# daric register map
Vendor: cramium
Registers are 32-bit, read-write, reset 0x0 unless marked. A register's access mark holds for its fields unless they carry their own. Offsets are from the block's base; [hi:lo] are bit positions; {n}, {i} and the like mark numbered series.

## UDMA_CAMERA
Base 0x5010F000
0x00 REG_RX_SADDR — See file:///F:/code/cram-nto/ips/udma/udma_camera/rtl/camera_reg_if.sv
  [11:0] r_rx_startaddr
0x04 REG_RX_SIZE — See file:///F:/code/cram-nto/ips/udma/udma_camera/rtl/camera_reg_if.sv
  [15:0] r_rx_size
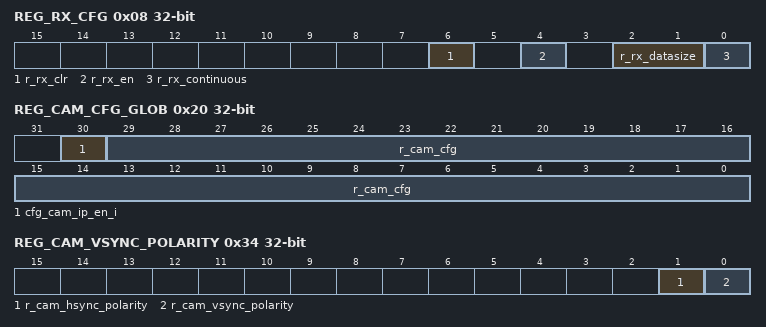
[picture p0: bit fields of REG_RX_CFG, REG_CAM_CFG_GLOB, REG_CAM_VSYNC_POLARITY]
0x08 REG_RX_CFG — See file:///F:/code/cram-nto/ips/udma/udma_camera/rtl/camera_reg_if.sv
  [6] r_rx_clr, [4] r_rx_en, [2:1] r_rx_datasize, [0] r_rx_continuous
0x20 REG_CAM_CFG_GLOB — See file:///F:/code/cram-nto/ips/udma/udma_camera/rtl/camera_reg_if.sv
  [30] cfg_cam_ip_en_i, [29:0] r_cam_cfg
0x24 REG_CAM_CFG_LL — See file:///F:/code/cram-nto/ips/udma/udma_camera/rtl/camera_reg_if.sv
  [31:0] r_cam_cfg_ll
0x28 REG_CAM_CFG_UR — See file:///F:/code/cram-nto/ips/udma/udma_camera/rtl/camera_reg_if.sv
  [31:0] r_cam_cfg_ur
0x2C REG_CAM_CFG_SIZE — See file:///F:/code/cram-nto/ips/udma/udma_camera/rtl/camera_reg_if.sv
  [31:0] r_cam_cfg_size
0x30 REG_CAM_CFG_FILTER — See file:///F:/code/cram-nto/ips/udma/udma_camera/rtl/camera_reg_if.sv
  [31:0] r_cam_cfg_filter
0x34 REG_CAM_VSYNC_POLARITY — See file:///F:/code/cram-nto/ips/udma/udma_camera/rtl/camera_reg_if.sv
  [1] r_cam_hsync_polarity, [0] r_cam_vsync_polarity

## UDMA_FILTER
Base 0x50110000
0x00 REG_TX_CH0_ADD — See file:///F:/code/cram-nto/ips/udma/udma_filter/rtl/udma_filter_reg_if.sv
  [14:0] r_filter_tx_start_addr_0
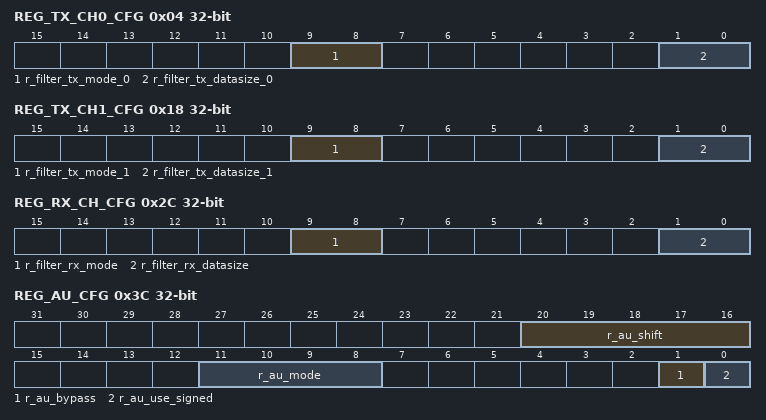
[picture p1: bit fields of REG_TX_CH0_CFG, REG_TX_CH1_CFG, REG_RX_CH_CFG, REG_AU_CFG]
0x04 REG_TX_CH0_CFG — See file:///F:/code/cram-nto/ips/udma/udma_filter/rtl/udma_filter_reg_if.sv
  [9:8] r_filter_tx_mode_0, [1:0] r_filter_tx_datasize_0
{0x8+4i} REG_TX_CH0_LEN{i} (i=0..2) — See file:///F:/code/cram-nto/ips/udma/udma_filter/rtl/udma_filter_reg_if.sv
  [14:0] r_filter_tx_len{i}_0
0x14 REG_TX_CH1_ADD — See file:///F:/code/cram-nto/ips/udma/udma_filter/rtl/udma_filter_reg_if.sv
  [14:0] r_filter_tx_start_addr_1
0x18 REG_TX_CH1_CFG — See file:///F:/code/cram-nto/ips/udma/udma_filter/rtl/udma_filter_reg_if.sv
  [9:8] r_filter_tx_mode_1, [1:0] r_filter_tx_datasize_1
{0x1C+4i} REG_TX_CH1_LEN{i} (i=0..2) — See file:///F:/code/cram-nto/ips/udma/udma_filter/rtl/udma_filter_reg_if.sv
  [14:0] r_filter_tx_len{i}_1
0x28 REG_RX_CH_ADD — See file:///F:/code/cram-nto/ips/udma/udma_filter/rtl/udma_filter_reg_if.sv
  [14:0] r_filter_rx_start_addr
0x2C REG_RX_CH_CFG — See file:///F:/code/cram-nto/ips/udma/udma_filter/rtl/udma_filter_reg_if.sv
  [9:8] r_filter_rx_mode, [1:0] r_filter_rx_datasize
{0x30+4i} REG_RX_CH_LEN{i} (i=0..2) — See file:///F:/code/cram-nto/ips/udma/udma_filter/rtl/udma_filter_reg_if.sv
  [15:0] r_filter_rx_len{i}
0x3C REG_AU_CFG — See file:///F:/code/cram-nto/ips/udma/udma_filter/rtl/udma_filter_reg_if.sv
  [20:16] r_au_shift, [11:8] r_au_mode, [1] r_au_bypass, [0] r_au_use_signed
0x40 REG_AU_REG0 — See file:///F:/code/cram-nto/ips/udma/udma_filter/rtl/udma_filter_reg_if.sv
  [31:0] r_commit_au_reg0
0x44 REG_AU_REG1 — See file:///F:/code/cram-nto/ips/udma/udma_filter/rtl/udma_filter_reg_if.sv
  [31:0] r_commit_au_reg1
0x48 REG_BINCU_TH — See file:///F:/code/cram-nto/ips/udma/udma_filter/rtl/udma_filter_reg_if.sv
  [31:0] r_commit_bincu_threshold
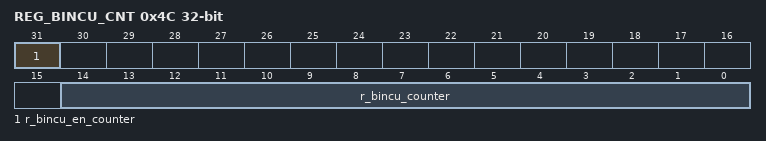
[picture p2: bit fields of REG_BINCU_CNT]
0x4C REG_BINCU_CNT — See file:///F:/code/cram-nto/ips/udma/udma_filter/rtl/udma_filter_reg_if.sv
  [31] r_bincu_en_counter, [14:0] r_bincu_counter
0x50 REG_BINCU_SETUP — See file:///F:/code/cram-nto/ips/udma/udma_filter/rtl/udma_filter_reg_if.sv
  [1:0] r_bincu_datasize
0x54 REG_BINCU_VAL — See file:///F:/code/cram-nto/ips/udma/udma_filter/rtl/udma_filter_reg_if.sv
  [14:0] bincu_counter_i
0x58 REG_FILT — See file:///F:/code/cram-nto/ips/udma/udma_filter/rtl/udma_filter_reg_if.sv
  [3:0] r_filter_mode
0x60 REG_STATUS — See file:///F:/code/cram-nto/ips/udma/udma_filter/rtl/udma_filter_reg_if.sv
  [0] r_filter_done

## UDMA_SCIF
Base 0x50111000
0x00 REG_RX_SADDR — See file:///F:/code/cram-nto/modules/ifsub/rtl/udma_scif_reg.sv
  [11:0] r_rx_startaddr
0x04 REG_RX_SIZE — See file:///F:/code/cram-nto/modules/ifsub/rtl/udma_scif_reg.sv
  [15:0] r_rx_size
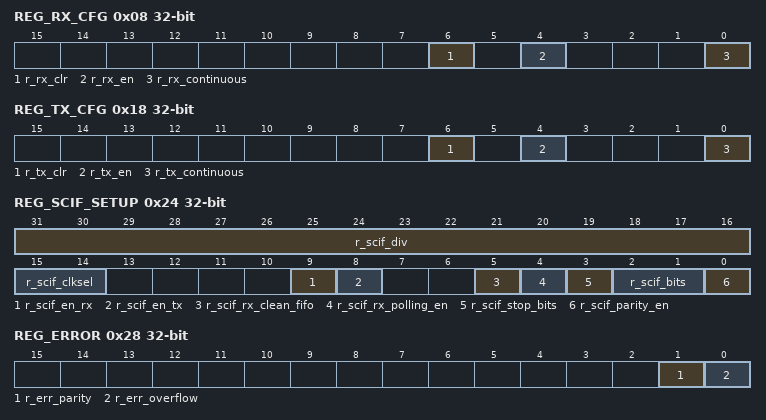
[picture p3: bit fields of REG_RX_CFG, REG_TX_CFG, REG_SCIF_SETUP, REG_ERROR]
0x08 REG_RX_CFG — See file:///F:/code/cram-nto/modules/ifsub/rtl/udma_scif_reg.sv
  [6] r_rx_clr, [4] r_rx_en, [0] r_rx_continuous
0x10 REG_TX_SADDR — See file:///F:/code/cram-nto/modules/ifsub/rtl/udma_scif_reg.sv
  [11:0] r_tx_startaddr
0x14 REG_TX_SIZE — See file:///F:/code/cram-nto/modules/ifsub/rtl/udma_scif_reg.sv
  [15:0] r_tx_size
0x18 REG_TX_CFG — See file:///F:/code/cram-nto/modules/ifsub/rtl/udma_scif_reg.sv
  [6] r_tx_clr, [4] r_tx_en, [0] r_tx_continuous
0x20 REG_STATUS — See file:///F:/code/cram-nto/modules/ifsub/rtl/udma_scif_reg.sv
  [0] status_i
0x24 REG_SCIF_SETUP — See file:///F:/code/cram-nto/modules/ifsub/rtl/udma_scif_reg.sv
  [31:16] r_scif_div, [15:14] r_scif_clksel, [9] r_scif_en_rx, [8] r_scif_en_tx, [5] r_scif_rx_clean_fifo, [4] r_scif_rx_polling_en, [3] r_scif_stop_bits, [2:1] r_scif_bits, [0] r_scif_parity_en
0x28 REG_ERROR — See file:///F:/code/cram-nto/modules/ifsub/rtl/udma_scif_reg.sv
  [1] r_err_parity, [0] r_err_overflow
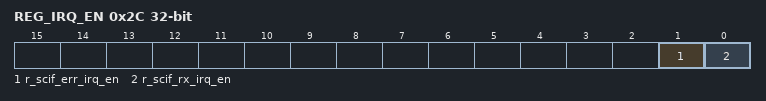
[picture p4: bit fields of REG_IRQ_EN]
0x2C REG_IRQ_EN — See file:///F:/code/cram-nto/modules/ifsub/rtl/udma_scif_reg.sv
  [1] r_scif_err_irq_en, [0] r_scif_rx_irq_en
0x30 REG_VALID — See file:///F:/code/cram-nto/modules/ifsub/rtl/udma_scif_reg.sv
  [0] r_scif_rx_data_valid
0x34 REG_DATA — See file:///F:/code/cram-nto/modules/ifsub/rtl/udma_scif_reg.sv
  [7:0] r_scif_rx_data
0x38 REG_SCIF_ETU — See file:///F:/code/cram-nto/modules/ifsub/rtl/udma_scif_reg.sv
  [15:0] r_scif_etu
